# ESP32-P4 register map
Vendor: ESPRESSIF SYSTEMS (SHANGHAI) CO., LTD.; Series: ESP32 P-Series; File version: 2
CPU: RV32IMAFC r0p0, little endian, no MPU, FPU, 0 interrupt priority bits
Address unit: 32 bits
Registers are 32-bit, read-write, reset 0x0 unless marked. A register's access mark holds for its fields unless they carry their own. Offsets are from the block's base; [hi:lo] are bit positions.

## PARL_IO — Parallel IO Controller
Base 0x500CF000
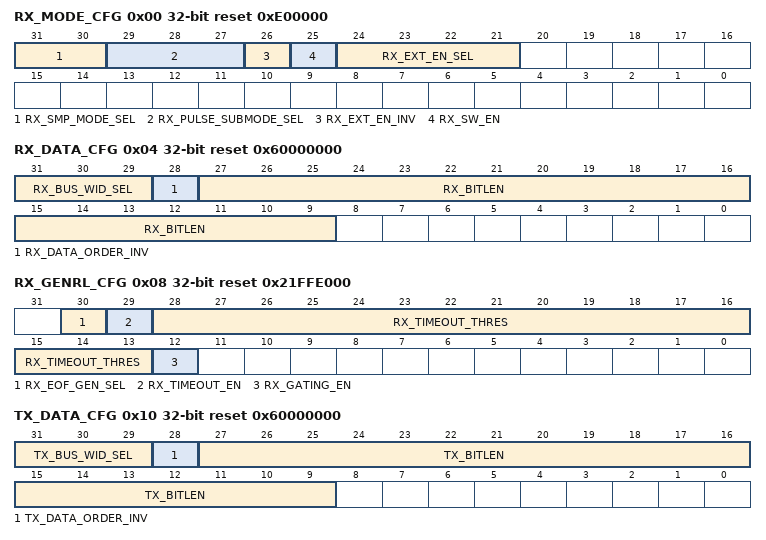
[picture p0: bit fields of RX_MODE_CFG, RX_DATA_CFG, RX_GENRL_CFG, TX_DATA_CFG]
0x00 RX_MODE_CFG reset 0xE00000 — Parallel RX Sampling mode configuration register.
  [31:30] RX_SMP_MODE_SEL — Configures the rxd sampling mode. 2'b00: external level enable mode 2'b01: external pulse enable mode 2'b10: internal software enable mode
  [29:27] RX_PULSE_SUBMODE_SEL — Configures the rxd pulse sampling submode. 4'd0: positive pulse start(data bit included) && positive pulse end(data bit included) 4'd1: positive pulse start(data bit included) && positive pulse end (data bit excluded) 4'd2: positive pulse start(data bit excluded) && positive pulse end (data bit included) 4'd3: positive pulse start(data bit excluded) && positive pulse end (data bit excluded) 4'd4: positive pulse start(data bit included) && length end 4'd5: positive pulse start(data bit excluded) && length end
  [26] RX_EXT_EN_INV — Set this bit to invert the external enable signal.
  [25] RX_SW_EN — Set this bit to enable data sampling by software.
  [24:21] RX_EXT_EN_SEL — Configures rx external enable signal selection from IO PAD.
0x04 RX_DATA_CFG reset 0x60000000 — Parallel RX data configuration register.
  [31:29] RX_BUS_WID_SEL — Configures the rxd bus width. 3'd0: bus width is 1. 3'd1: bus width is 2. 3'd2: bus width is 4. 3'd3: bus width is 8.
  [28] RX_DATA_ORDER_INV — Set this bit to invert bit order of one byte sent from RX_FIFO to DMA.
  [27:9] RX_BITLEN — Configures expected byte number of received data.
0x08 RX_GENRL_CFG reset 0x21FFE000 — Parallel RX general configuration register.
  [30] RX_EOF_GEN_SEL — Configures the DMA eof generated mechanism. 1'b0: eof generated by data bit length. 1'b1: eof generated by external enable signal.
  [29] RX_TIMEOUT_EN — Set this bit to enable timeout function to generate error eof.
  [28:13] RX_TIMEOUT_THRES — Configures threshold of timeout counter.
  [12] RX_GATING_EN — Set this bit to enable the clock gating of output rx clock.
0x0C RX_START_CFG — Parallel RX Start configuration register.
  [31] RX_START — Set this bit to start rx data sampling.
0x10 TX_DATA_CFG reset 0x60000000 — Parallel TX data configuration register.
  [31:29] TX_BUS_WID_SEL — Configures the txd bus width. 3'd0: bus width is 1. 3'd1: bus width is 2. 3'd2: bus width is 4. 3'd3: bus width is 8.
  [28] TX_DATA_ORDER_INV — Set this bit to invert bit order of one byte sent from TX_FIFO to IO data.
  [27:9] TX_BITLEN — Configures expected byte number of sent data.
0x14 TX_START_CFG — Parallel TX Start configuration register.
  [31] TX_START — Set this bit to start tx data transmit.
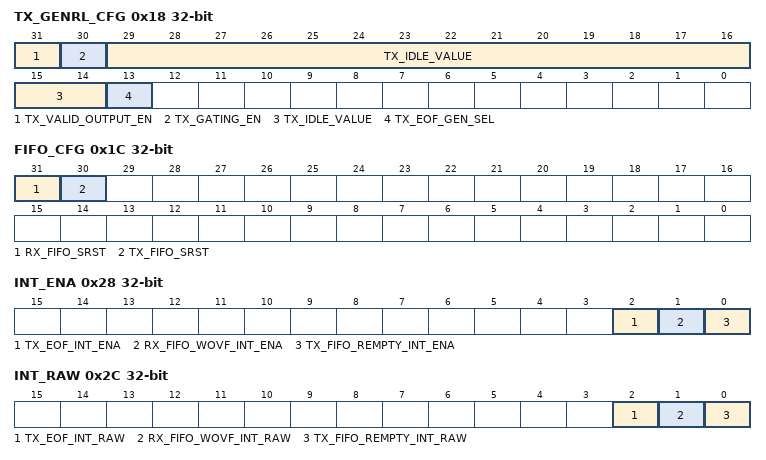
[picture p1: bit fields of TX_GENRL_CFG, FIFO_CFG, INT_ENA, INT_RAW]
0x18 TX_GENRL_CFG — Parallel TX general configuration register.
  [31] TX_VALID_OUTPUT_EN — Set this bit to enable the output of tx data valid signal.
  [30] TX_GATING_EN — Set this bit to enable the clock gating of output tx clock.
  [29:14] TX_IDLE_VALUE — Configures bus value of transmitter in IDLE state.
  [13] TX_EOF_GEN_SEL — Configures the tx eof generated mechanism. 1'b0: eof generated by data bit length. 1'b1: eof generated by DMA eof.
0x1C FIFO_CFG — Parallel IO FIFO configuration register.
  [31] RX_FIFO_SRST — Set this bit to reset async fifo in rx module.
  [30] TX_FIFO_SRST — Set this bit to reset async fifo in tx module.
0x20 REG_UPDATE wo — Parallel IO FIFO configuration register.
  [31] RX_REG_UPDATE — Set this bit to update rx register configuration.
0x24 ST ro — Parallel IO module status register0.
  [31] TX_READY — Represents the status that tx is ready to transmit.
0x28 INT_ENA — Parallel IO interrupt enable singal configuration register.
  [2] TX_EOF_INT_ENA — Set this bit to enable TX_EOF_INT.
  [1] RX_FIFO_WOVF_INT_ENA — Set this bit to enable RX_FIFO_WOVF_INT.
  [0] TX_FIFO_REMPTY_INT_ENA — Set this bit to enable TX_FIFO_REMPTY_INT.
0x2C INT_RAW — Parallel IO interrupt raw singal status register.
  [2] TX_EOF_INT_RAW — The raw interrupt status of TX_EOF_INT.
  [1] RX_FIFO_WOVF_INT_RAW — The raw interrupt status of RX_FIFO_WOVF_INT.
  [0] TX_FIFO_REMPTY_INT_RAW — The raw interrupt status of TX_FIFO_REMPTY_INT.
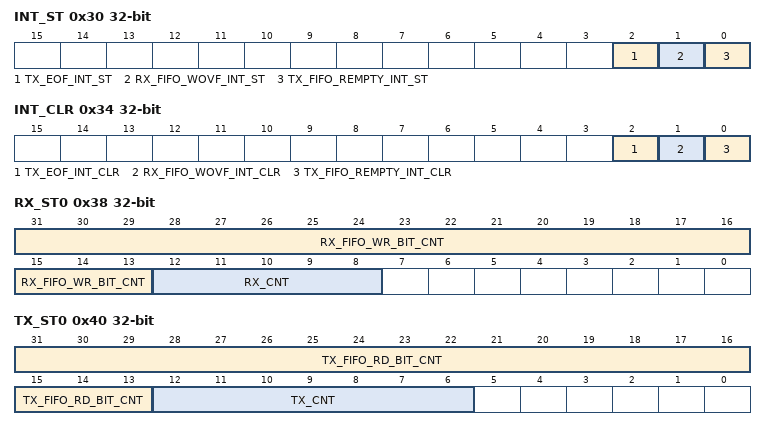
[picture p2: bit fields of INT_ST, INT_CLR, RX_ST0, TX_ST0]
0x30 INT_ST ro — Parallel IO interrupt singal status register.
  [2] TX_EOF_INT_ST — The masked interrupt status of TX_EOF_INT.
  [1] RX_FIFO_WOVF_INT_ST — The masked interrupt status of RX_FIFO_WOVF_INT.
  [0] TX_FIFO_REMPTY_INT_ST — The masked interrupt status of TX_FIFO_REMPTY_INT.
0x34 INT_CLR wo — Parallel IO interrupt clear singal configuration register.
  [2] TX_EOF_INT_CLR — Set this bit to clear TX_EOF_INT.
  [1] RX_FIFO_WOVF_INT_CLR — Set this bit to clear RX_FIFO_WOVF_INT.
  [0] TX_FIFO_REMPTY_INT_CLR — Set this bit to clear TX_FIFO_REMPTY_INT.
0x38 RX_ST0 ro — Parallel IO RX status register0
  [31:13] RX_FIFO_WR_BIT_CNT — Indicates the current written bit number into Rx FIFO.
  [12:8] RX_CNT — Indicates the cycle number of reading Rx FIFO.
0x3C RX_ST1 ro — Parallel IO RX status register1
  [31:13] RX_FIFO_RD_BIT_CNT — Indicates the current read bit number from Rx FIFO.
0x40 TX_ST0 ro — Parallel IO TX status register0
  [31:13] TX_FIFO_RD_BIT_CNT — Indicates the current read bit number from Tx FIFO.
  [12:6] TX_CNT — Indicates the cycle number of reading Tx FIFO.
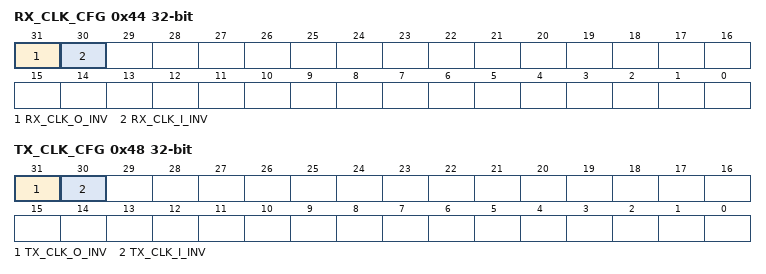
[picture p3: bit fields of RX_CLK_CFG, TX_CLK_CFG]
0x44 RX_CLK_CFG — Parallel IO RX clk configuration register
  [31] RX_CLK_O_INV — Set this bit to invert the output Rx core clock.
  [30] RX_CLK_I_INV — Set this bit to invert the input Rx core clock.
0x48 TX_CLK_CFG — Parallel IO TX clk configuration register
  [31] TX_CLK_O_INV — Set this bit to invert the output Tx core clock.
  [30] TX_CLK_I_INV — Set this bit to invert the input Tx core clock.
0x120 CLK — Parallel IO clk configuration register
  [31] EN — Force clock on for this register file
0x3FC VERSION reset 0x2212260
  [27:0] DATE — Version of this register file
